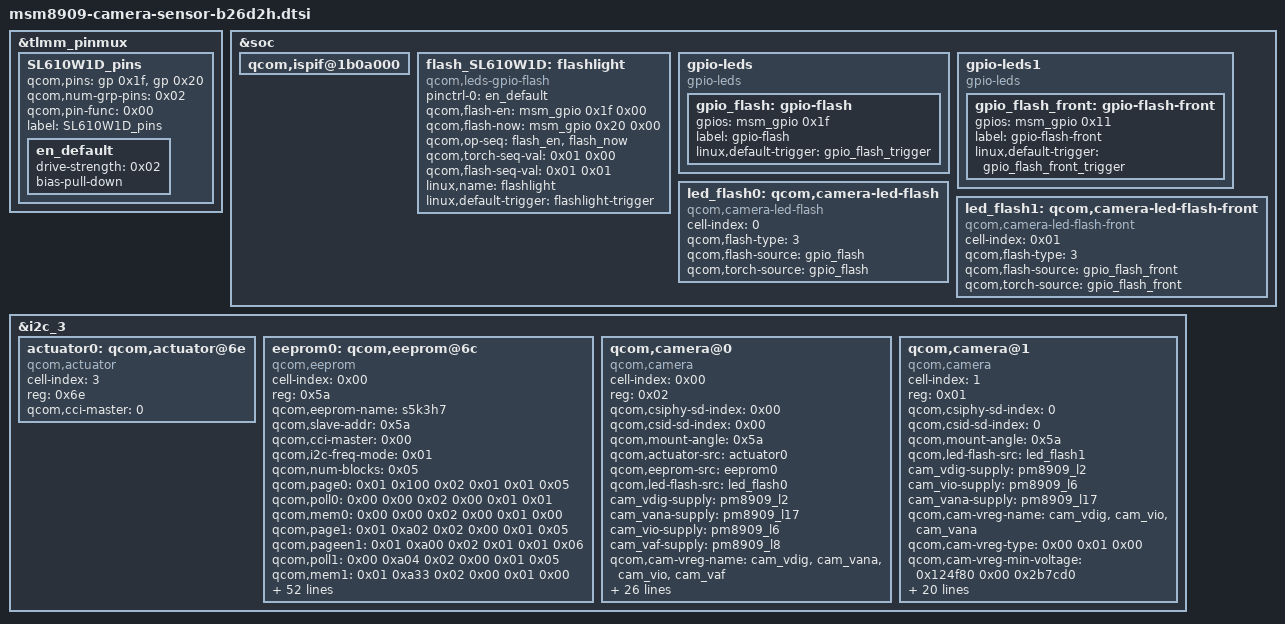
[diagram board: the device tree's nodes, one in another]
/*
 * Copyright (c) 2014, The Linux Foundation. All rights reserved.
 *
 * This program is free software; you can redistribute it and/or modify
 * it under the terms of the GNU General Public License version 2 and
 * only version 2 as published by the Free Software Foundation.
 *
 * This program is distributed in the hope that it will be useful,
 * but WITHOUT ANY WARRANTY; without even the implied warranty of
 * MERCHANTABILITY or FITNESS FOR A PARTICULAR PURPOSE.  See the
 * GNU General Public License for more details.
 * to add regulator 	vdd-supply = <&gdsc_vfe>
 */
&tlmm_pinmux {
	SL610W1D_pins {
		qcom,pins = <&gp 0x1f>,<&gp 0x20 >;
		qcom,num-grp-pins = <0x02>;
		qcom,pin-func = <0x00>;
		label = "SL610W1D_pins";

		en_default: en_default {
			drive-strength = <0x02>;
			bias-pull-down;
		};
	};
};

&soc {
	qcom,ispif@1b0a000 {
		/delete-property/ vdd-supply;
	};

	flash_SL610W1D:flashlight {
		compatible = "qcom,leds-gpio-flash";
		status = "okay";
		pinctrl-names = "flash_default";
		pinctrl-0 = <&en_default>;
		qcom,flash-en = <&msm_gpio 0x1f 0x00 >;
		qcom,flash-now = <&msm_gpio 0x20 0x00 >;
		qcom,op-seq = "flash_en","flash_now";
		qcom,torch-seq-val = < 0x01 0x00 >;
		qcom,flash-seq-val = < 0x01 0x01 >;
		linux,name = "flashlight";
		linux,default-trigger = "flashlight-trigger";
	};

	gpio-leds {
		compatible = "gpio-leds";
		status = "ok";

		gpio_flash: gpio-flash {
			gpios = <&msm_gpio 0x1f 0x00>;
			label = "gpio-flash";
			linux,default-trigger = "gpio_flash_trigger";
		};
	};

	gpio-leds1 {
		compatible = "gpio-leds";
		status = "ok";

		gpio_flash_front: gpio-flash-front {
			gpios = <&msm_gpio 0x11 0x00 >;
			label = "gpio-flash-front";
			linux,default-trigger = "gpio_flash_front_trigger";
		};
	};

	led_flash0: qcom,camera-led-flash {
		cell-index = <0>;
		compatible = "qcom,camera-led-flash";
		qcom,flash-type = <3>;
		qcom,flash-source = <&gpio_flash>;
		qcom,torch-source = <&gpio_flash>;
	};

	led_flash1: qcom,camera-led-flash-front {
		cell-index = < 0x01 >;
		compatible = "qcom,camera-led-flash-front";
		qcom,flash-type = <3>;
		qcom,flash-source = <&gpio_flash_front>;
		qcom,torch-source = <&gpio_flash_front>;
	};
};

&i2c_3 {
	actuator0: qcom,actuator@6e {
		cell-index = <3>;
		reg = <0x6e>;
		compatible = "qcom,actuator";
		qcom,cci-master = <0>;
	};

	eeprom0: qcom,eeprom@6c {
		cell-index = < 0x00 >;
		reg = < 0x5a >;
		qcom,eeprom-name = "s5k3h7";
		compatible = "qcom,eeprom";
		qcom,slave-addr = < 0x5a >;
		qcom,cci-master = < 0x00 >;
		qcom,i2c-freq-mode = < 0x01 >;
		qcom,num-blocks = < 0x05 >;
		qcom,page0 = < 0x01 0x100 0x02 0x01 0x01 0x05 >;
		qcom,poll0 = < 0x00 0x00 0x02 0x00 0x01 0x01 >;
		qcom,mem0 = < 0x00 0x00 0x02 0x00 0x01 0x00 >;
		qcom,page1 = < 0x01 0xa02 0x02 0x00 0x01 0x05 >;
		qcom,pageen1 = < 0x01 0xa00 0x02 0x01 0x01 0x06 >;
		qcom,poll1 = < 0x00 0xa04 0x02 0x00 0x01 0x05 >;
		qcom,mem1 = < 0x01 0xa33 0x02 0x00 0x01 0x00 >;
		qcom,page2 = < 0x01 0xa02 0x02 0x01 0x01 0x05 >;
		qcom,pageen2 = < 0x01 0xa00 0x02 0x01 0x01 0x06 >;
		qcom,poll2 = < 0x00 0xa04 0x02 0x00 0x01 0x05 >;
		qcom,mem2 = < 0x07 0xa04 0x02 0x00 0x01 0x00 >;
		qcom,page3 = < 0x01 0xa02 0x02 0x02 0x01 0x05 >;
		qcom,pageen3 = < 0x01 0xa00 0x02 0x01 0x01 0x06 >;
		qcom,poll3 = < 0x00 0xa04 0x02 0x00 0x01 0x05 >;
		qcom,mem3 = < 0x07 0xa04 0x02 0x00 0x01 0x00 >;
		qcom,page4 = < 0x01 0xa00 0x02 0x00 0x01 0x01 >;
		qcom,poll4 = < 0x00 0x00 0x02 0x00 0x01 0x01 >;
		qcom,mem4 = < 0x00 0x00 0x02 0x00 0x01 0x00 >;
		cam_vdig-supply = <&pm8909_l2>;
		cam_vana-supply = <&pm8909_l17>;
		cam_vio-supply = <&pm8909_l6>;
		cam_vaf-supply = <&pm8909_l8>;
		qcom,cam-vreg-name = "cam_vdig","cam_vio","cam_vana","cam_vaf";
		qcom,cam-vreg-min-voltage = < 0x124f80 0x00 0x2b7cd0 0x2b7cd0 >;
		qcom,cam-vreg-max-voltage = < 0x124f80 0x00 0x2b7cd0 0x2c4020 >;
		qcom,cam-vreg-op-mode = < 0x30d40 0x00 0x13880 0x186a0 >;
		pinctrl-names = "cam_default","cam_suspend";
		pinctrl-0 = <&cam_sensor_mclk0_default &cam_sensor_rear_default>;
		pinctrl-1 = <&cam_sensor_mclk0_sleep &cam_sensor_rear_sleep>;
		gpios = <&msm_gpio 0x1a 0x00>,
				<&msm_gpio 0x23 0x00>,
				<&msm_gpio 0x22 0x00>,
				<&msm_gpio 0x00 0x00>,
				<&msm_gpio 0x01 0x00 >;
		qcom,gpio-reset = <1>;
		qcom,gpio-standby = <2>;
		qcom,gpio-vana = <3>;
		qcom,gpio-vdig = <4>;
		qcom,gpio-req-tbl-num = < 0x00 0x01 0x02 0x03 0x04 >;
		qcom,gpio-req-tbl-flags = < 0x01 0x00 0x00 0x00 0x00 >;
		qcom,gpio-req-tbl-label = "CAMIF_MCLK","CAM_RESET1","CAM_STANDBY","CAM_VANA","CAM_VDIG";
		qcom,cam-power-seq-type = "sensor_vreg","sensor_gpio","sensor_gpio","sensor_gpio","sensor_clk","sensor_gpio";
		qcom,cam-power-seq-val = "cam_vio","sensor_gpio_vana","sensor_gpio_vdig","sensor_gpio_standby","sensor_cam_mclk","sensor_gpio_reset";
		qcom,cam-power-seq-cfg-val = < 0x01 0x01 0x01 0x01 0x16c6140 0x01 >;
		qcom,cam-power-seq-delay = < 0x05 0x05 0x05 0x0a 0x05 0x05 >;
		clocks = <&clock_gcc clk_mclk0_clk_src>,
			<&clock_gcc clk_gcc_camss_mclk0_clk>;
		clock-names = "cam_src_clk","cam_clk";
	};

	qcom,camera@0 {
		cell-index = < 0x00 >;
		compatible = "qcom,camera";
		reg = < 0x02 >;
		qcom,csiphy-sd-index = < 0x00 >;
		qcom,csid-sd-index = < 0x00 >;
		qcom,mount-angle = < 0x5a >;
		qcom,actuator-src = <&actuator0>;
		qcom,eeprom-src = <&eeprom0>;
		qcom,led-flash-src = <&led_flash0>;
		cam_vdig-supply = <&pm8909_l2>;
		cam_vana-supply = <&pm8909_l17>;
		cam_vio-supply = <&pm8909_l6>;
		cam_vaf-supply = <&pm8909_l8>;
		qcom,cam-vreg-name = "cam_vdig","cam_vana","cam_vio","cam_vaf";
		qcom,cam-vreg-type = < 0x00 0x01 0x00 0x00 >;
		qcom,cam-vreg-min-voltage = < 0x124f80 0x00 0x2b7cd0 0x2b7cd0 >;
		qcom,cam-vreg-max-voltage = < 0x124f80 0x00 0x2b7cd0 0x2c4020 >;
		qcom,cam-vreg-op-mode = < 0x30d40 0x00 0x13880 0x186a0 >;
		pinctrl-names = "cam_default","cam_suspend";
		pinctrl-0 = <&cam_sensor_mclk0_default &cam_sensor_rear_default>;
		pinctrl-1 = <&cam_sensor_mclk0_sleep &cam_sensor_rear_sleep>;
		gpios = <&msm_gpio 0x1a 0x00>,
				<&msm_gpio 0x23 0x00>,
				<&msm_gpio 0x22 0x00>,
				<&msm_gpio 0x00 0x00>,
				<&msm_gpio 0x01 0x00>;
		qcom,gpio-reset = <1>;
		qcom,gpio-standby = <2>;
		qcom,gpio-vana = <3>;
		qcom,gpio-vdig = <4>;
		qcom,gpio-req-tbl-num = <0 1 2 3 4>;
		qcom,gpio-req-tbl-flags = <1 0 0 0 0>;
		qcom,gpio-req-tbl-label = "CAMIF_MCLK","CAM_RESET1","CAM_STANDBY","CAM_VANA","CAM_VDIG";
		qcom,sensor-position = < 0x00 >;
		qcom,sensor-mode = < 0x00 >;
		qcom,cci-master = < 0x00 >;
		status = "ok";
		clocks = <&clock_gcc clk_mclk0_clk_src>,
				<&clock_gcc clk_gcc_camss_mclk0_clk>;
		clock-names = "cam_src_clk","cam_clk";
	};

	qcom,camera@1 {
		cell-index = <1>;
		compatible = "qcom,camera";
		reg = < 0x01 >;
		qcom,csiphy-sd-index = <0>;
		qcom,csid-sd-index = <0>;
		qcom,mount-angle = < 0x5a >;
		qcom,led-flash-src = <&led_flash1>;
		cam_vdig-supply = <&pm8909_l2>;
		cam_vio-supply = <&pm8909_l6>;
		cam_vana-supply = <&pm8909_l17>;
		qcom,cam-vreg-name = "cam_vdig","cam_vio","cam_vana";
		qcom,cam-vreg-type = < 0x00 0x01 0x00 >;
		qcom,cam-vreg-min-voltage = < 0x124f80 0x00 0x2b7cd0 >;
		qcom,cam-vreg-max-voltage = < 0x124f80 0x00 0x2b7cd0 >;
		qcom,cam-vreg-op-mode = < 0x30d40 0x00 0x13880 >;
		pinctrl-names = "cam_default","cam_suspend";
		pinctrl-0 = <&cam_sensor_mclk1_default &cam_sensor_front_default>;
		pinctrl-1 = <&cam_sensor_mclk1_sleep &cam_sensor_front_sleep>;
		gpios = <&msm_gpio 0x1b 0x00>,
				<&msm_gpio 0x1c 0x00>,
				<&msm_gpio 0x00 0x00>,
				<&msm_gpio 0x01 0x00>,
				<&msm_gpio 0x21 0x00>;
		qcom,gpio-reset = <1>;
		qcom,gpio-vana = <2>;
		qcom,gpio-vdig = <3>;
		qcom,gpio-standby = <4>;
		qcom,gpio-req-tbl-num = <0 1 2 3 4>;
		qcom,gpio-req-tbl-flags = <1 0 0 0 0>;
		qcom,gpio-req-tbl-label = "CAMIF_MCLK","CAM_RESET","CAM_VANA","CAM_VDIG","CAM_STANDBY";
		qcom,cci-master = < 0x00 >;
		status = "ok";
		clocks = <&clock_gcc clk_mclk1_clk_src>,
				<&clock_gcc clk_gcc_camss_mclk1_clk>;
		clock-names = "cam_src_clk","cam_clk";
	};
};
